LIN_description_file;
LIN_protocol_version = "2.1";
LIN_language_version = "2.1";
LIN_speed = 9.6 kbps;

Nodes {
  Master: Gateway2, 5 ms, 0.1 ms ;
  Slaves: SlaveA, SlaveB, SlaveC ;
}

Signals {
  Cluster2PotentiometerA: 8, 0, SlaveA, Gateway2;
  Cluster2LightSensorA: 8, 0, SlaveA, Gateway2;
  Cluster2SlaveAError: 1, 0, SlaveA, Gateway2;
  Cluster2PotentiometerB: 8, 0, SlaveB, Gateway2;
  Cluster2SlaveBError: 1, 0, SlaveB, Gateway2;
  Cluster2PotentiometerC: 8, 0, SlaveC, Gateway2;
  Cluster2SlaveCError: 1, 0, SlaveC, Gateway2;
  SlaveIdentifier: 2, 0, Gateway2, SlaveA, SlaveB, SlaveC;
  ResetSignal: 2, 0, Gateway2, SlaveA, SlaveB, SlaveC;
}

Frames {
  ResetFrame: 8, Gateway2, 1 {
  ResetSignal, 0;
  }

  LedControl: 9, Gateway2, 1 {
  SlaveIdentifier, 0;
  }
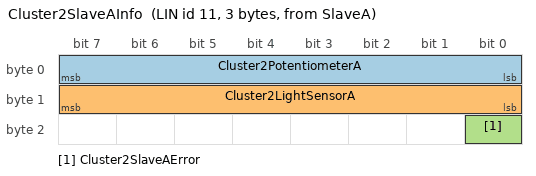
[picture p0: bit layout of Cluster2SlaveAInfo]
  Cluster2SlaveAInfo: 11, SlaveA, 3 {
  Cluster2PotentiometerA, 0;
  Cluster2LightSensorA, 8;
  Cluster2SlaveAError, 16;
  }
  Cluster2SlaveBInfo: 12, SlaveB, 2 {
  Cluster2PotentiometerB, 0;
  Cluster2SlaveBError, 8;
  }
  Cluster2SlaveCInfo: 13, SlaveC, 2 {
  Cluster2PotentiometerC, 0;
  Cluster2SlaveCError, 8;
  }
}

Sporadic_frames {
  LedControlFrame: LedControl;
  ResetControlFrame: ResetFrame;
}

Node_attributes {
  SlaveA{
    LIN_protocol = "2.1" ;
    configured_NAD = 0x4 ;
    initial_NAD = 0xd ;
    product_id = 0x21, 0x4, 3 ;
  response_error = Cluster2SlaveAError;
    P2_min = 100 ms ;
    ST_min = 20 ms ;
    N_As_timeout = 1000 ms ;
    N_Cr_timeout = 1000 ms ;
    configurable_frames {
    LedControl;
    ResetFrame;
    Cluster2SlaveAInfo ;
    LedControlFrame;
    ResetControlFrame;
    }
  }
  SlaveB{
    LIN_protocol = "2.1" ;
    configured_NAD = 0x5 ;
    initial_NAD = 0xe ;
    product_id = 0x22, 0x5, 4 ;
  response_error = Cluster2SlaveBError;
    P2_min = 100 ms ;
    ST_min = 20 ms ;
    N_As_timeout = 1000 ms ;
    N_Cr_timeout = 1000 ms ;
    configurable_frames {
    LedControl;
    ResetFrame;
    Cluster2SlaveBInfo ;
    LedControlFrame;
    ResetControlFrame;
    }
  }
  SlaveC{
    LIN_protocol = "2.1" ;
    configured_NAD = 0x6 ;
    initial_NAD = 0xf ;
    product_id = 0x23, 0x6, 5 ;
  response_error = Cluster2SlaveCError;
    P2_min = 100 ms ;
    ST_min = 20 ms ;
    N_As_timeout = 1000 ms ;
    N_Cr_timeout = 1000 ms ;
    configurable_frames {
    LedControl;
    ResetFrame;
    Cluster2SlaveCInfo ;
    LedControlFrame;
    ResetControlFrame;
    }
  }
}

Schedule_tables {
  NormalTable {
    Cluster2SlaveAInfo delay 100 ms ;
    Cluster2SlaveBInfo delay 100 ms ;
  Cluster2SlaveCInfo delay 100 ms ;
    LedControlFrame delay 50 ms ;
  ResetControlFrame delay 50 ms ;
  }

  ResetTable {
     ResetControlFrame delay 50 ms ;
  }

  PeriodicalWakeupTable {
    Cluster2SlaveAInfo delay 100 ms ;
    Cluster2SlaveBInfo delay 100 ms ;
  Cluster2SlaveCInfo delay 100 ms ;
    LedControlFrame delay 50 ms ;
  ResetControlFrame delay 50 ms ;
  }

}
